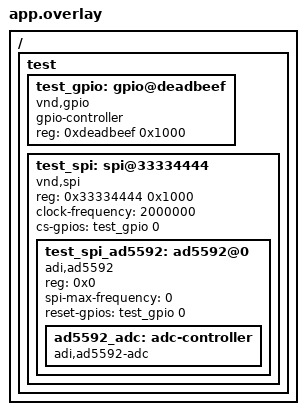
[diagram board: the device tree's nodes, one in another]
/*
 * Copyright (c) 2023 Grinn
 *
 * SPDX-License-Identifier: Apache-2.0
 *
 * Application overlay for testing driver builds
 *
 * Names in this file should be chosen in a way that won't conflict
 * with real-world devicetree nodes, to allow these tests to run on
 * (and be extended to test) real hardware.
 */

/ {
	test {
		#address-cells = <1>;
		#size-cells = <1>;

		test_gpio: gpio@deadbeef {
			compatible = "vnd,gpio";
			gpio-controller;
			reg = <0xdeadbeef 0x1000>;
			#gpio-cells = <0x2>;
			status = "okay";
		};

		test_spi: spi@33334444 {
			#address-cells = <1>;
			#size-cells = <0>;
			compatible = "vnd,spi";
			reg = <0x33334444 0x1000>;
			status = "okay";
			clock-frequency = <2000000>;

			cs-gpios = <&test_gpio 0 0>;

			test_spi_ad5592: ad5592@0 {
				compatible = "adi,ad5592";
				status = "okay";
				reg = <0x0>;
				spi-max-frequency = <0>;
				reset-gpios = <&test_gpio 0 0>;

				ad5592_adc: adc-controller {
					compatible = "adi,ad5592-adc";
					#io-channel-cells = <1>;
				};
			};
		};
	};
};
